# nrf54l10_flpr register map
Vendor: Nordic Semiconductor; Series: nrf54l; File version: 1
Registers are 32-bit, read-write, reset 0x0 unless marked. A register's access mark holds for its fields unless they carry their own. Offsets are from the block's base; [hi:lo] are bit positions; lines under a group give offsets from that group; {n}, {i} and the like mark numbered series; 'fields as' and 'values as' point back to an identical list.

## GLOBAL_GLITCHDET_S — Voltage glitch detectors
Base 0x5004B000
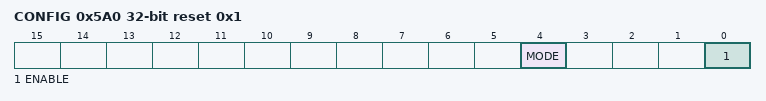
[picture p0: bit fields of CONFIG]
0x5A0 CONFIG reset 0x1 — Configuration for glitch detector
  [4] MODE — Glitch detector mode
    0=High pass filter mode; 1=Cap divider mode
  [0] ENABLE — Enable glitch detector
    0=Disable glitch detector; 1=Enable glitch detector

## GLOBAL_P2_NS — GPIO Port 0
Base 0x40050400
Same registers: GLOBAL_P1_NS 0x400D8200, GLOBAL_P0_NS 0x4010A000, GLOBAL_P2_S 0x50050400, GLOBAL_P1_S 0x500D8200, GLOBAL_P0_S 0x5010A000
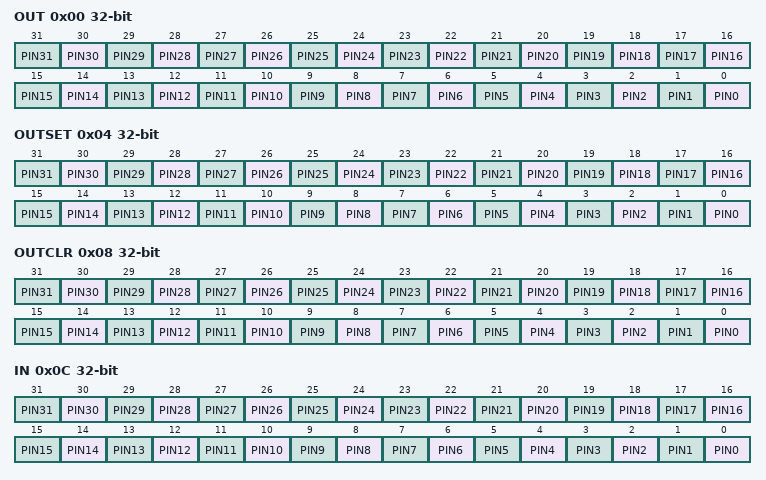
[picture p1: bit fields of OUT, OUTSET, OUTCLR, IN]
0x00 OUT — Write GPIO port
  [all] fields
    0=Low (Pin driver is low); 1=High (Pin driver is high)
  [n] PIN{n} (n=0..31)
0x04 OUTSET write-1-sets — Set individual bits in GPIO port
  [all] fields
    on read: 0=Low (Read: pin driver is low); 1=High (Read: pin driver is high) | on write: 1=Set (Write: writing a '1' sets the pin high; writing a '0' has no effect)
  [n] PIN{n} (n=0..31)
0x08 OUTCLR write-1-clears — Clear individual bits in GPIO port
  [all] fields
    on read: 0=Low (Read: pin driver is low); 1=High (Read: pin driver is high) | on write: 1=Clear (Write: writing a '1' sets the pin low; writing a '0' has no effect)
  [n] PIN{n} (n=0..31)
0x0C IN ro — Read GPIO port
  [all] fields
    0=Low (Pin input is low); 1=High (Pin input is high)
  [n] PIN{n} (n=0..31)
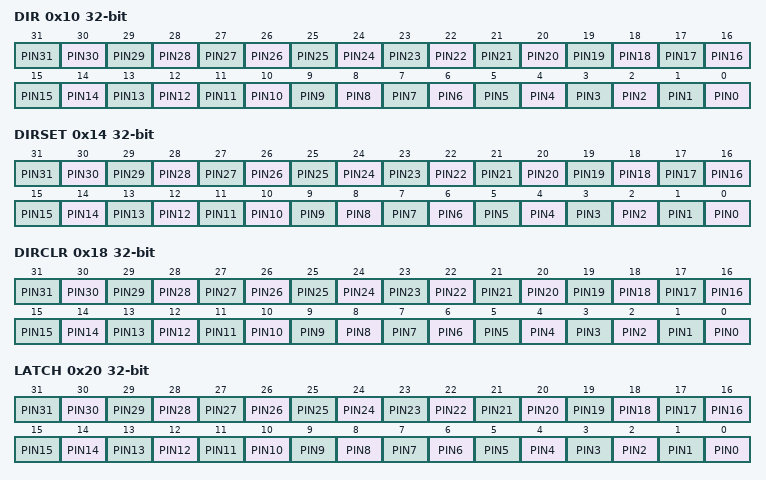
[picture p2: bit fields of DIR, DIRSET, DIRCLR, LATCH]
0x10 DIR — Direction of GPIO pins
  [all] fields
    0=Input (Pin set as input); 1=Output (Pin set as output)
  [n] PIN{n} (n=0..31)
0x14 DIRSET write-1-sets
  [all] fields
    on read: 0=Input (Read: pin set as input); 1=Output (Read: pin set as output) | on write: 1=Set (Write: writing a '1' sets pin to output; writing a '0' has no effect)
  [n] PIN{n} (n=0..31) — Set as output pin {n}
0x18 DIRCLR write-1-clears — DIR clear register
  [all] fields
    on read: 0=Input (Read: pin set as input); 1=Output (Read: pin set as output) | on write: 1=Clear (Write: writing a '1' sets pin to input; writing a '0' has no effect)
  [n] PIN{n} (n=0..31) — Set as input pin {n}
0x20 LATCH — Latch register indicating what GPIO pins that have met the criteria set in the PIN_CNF[n].SENSE registers
  [all] fields
    0=NotLatched (Criteria has not been met); 1=Latched (Criteria has been met)
  [n] PIN{n} (n=0..31) — Status on whether PIN{n} has met criteria set in PIN_CNF[{n}].SENSE register. Write '1' to clear.
0x24 DETECTMODE — Select between default DETECT signal behavior and LDETECT mode
  [0] DETECTMODE
    0=Default (DETECT directly connected to PIN DETECT signals); 1=LDETECT (Use the latched LDETECT behavior)
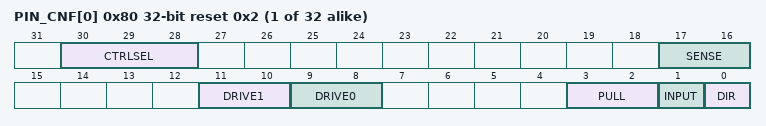
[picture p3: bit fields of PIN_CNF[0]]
{0x80+4i} PIN_CNF[{i}] (i=0..31) reset 0x2 — Description collection: Pin n configuration of GPIO pin
  [30:28] CTRLSEL — Select which module has direct control over this pin
    0=GPIO (GPIO or peripherals with PSEL registers); 1=VPR (VPR processor); 4=GRTC (GRTC peripheral)
  [17:16] SENSE — Pin sensing mechanism
    0=Disabled; 2=High (Sense for high level); 3=Low (Sense for low level)
  [11:10] DRIVE1 — Drive configuration for '1'
    0=S1 (Standard '1'); 1=H1 (High drive '1'); 2=D1 (Disconnect '1'(normally used for wired-or connections)); 3=E1 (Extra high drive '1')
  [9:8] DRIVE0 — Drive configuration for '0'
    0=S0 (Standard '0'); 1=H0 (High drive '0'); 2=D0 (Disconnect '0'(normally used for wired-or connections)); 3=E0 (Extra high drive '0')
  [3:2] PULL — Pull configuration
    0=Disabled (No pull); 1=Pull down on pin; 3=Pull up on pin
  [1] INPUT — Connect or disconnect input buffer
    0=Connect input buffer; 1=Disconnect input buffer
  [0] DIR — Pin direction. Same physical register as DIR register
    0=Input (Configure pin as an input pin); 1=Output (Configure pin as an output pin)

## GLOBAL_CTRLAP_NS — Control access port 0
Base 0x40052000
Same registers: GLOBAL_CTRLAP_S 0x50052000
0x100 EVENTS_RXREADY — RXSTATUS is changed to DataPending.
  [0] EVENTS_RXREADY
    0=NotGenerated (Event not generated); 1=Generated (Event generated)
0x104 EVENTS_TXDONE — TXSTATUS is changed to NoDataPending.
  [0] EVENTS_TXDONE
    values as EVENTS_RXREADY.EVENTS_RXREADY
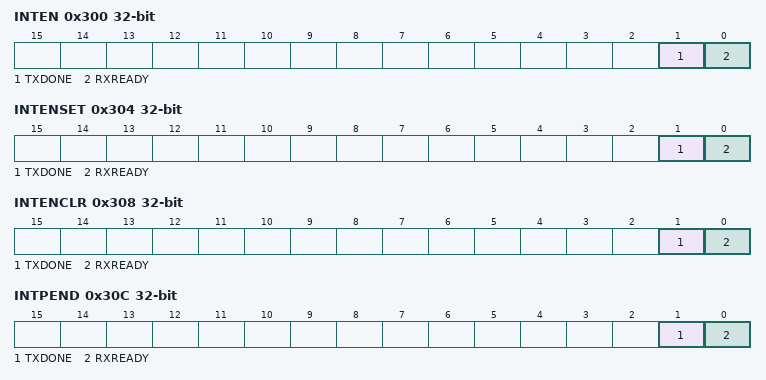
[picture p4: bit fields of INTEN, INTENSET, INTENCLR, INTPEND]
0x300 INTEN — Enable or disable interrupt
  [1] TXDONE — Enable or disable interrupt for event TXDONE
    0=Disabled; 1=Enabled
  [0] RXREADY — Enable or disable interrupt for event RXREADY
    0=Disabled; 1=Enabled
0x304 INTENSET — Enable interrupt
  [1] TXDONE — Write '1' to enable interrupt for event TXDONE
    on read: 0=Disabled (Read: Disabled); 1=Enabled (Read: Enabled) | on write: 1=Set (Enable)
  [0] RXREADY — Write '1' to enable interrupt for event RXREADY
    values as TXDONE
0x308 INTENCLR — Disable interrupt
  [1] TXDONE — Write '1' to disable interrupt for event TXDONE
    on read: 0=Disabled (Read: Disabled); 1=Enabled (Read: Enabled) | on write: 1=Clear (Disable)
  [0] RXREADY — Write '1' to disable interrupt for event RXREADY
    values as TXDONE
0x30C INTPEND ro — Pending interrupts
  [1] TXDONE — Read pending status of interrupt for event TXDONE
    on read: 0=NotPending (Read: Not pending); 1=Pending (Read: Pending)
  [0] RXREADY — Read pending status of interrupt for event RXREADY
    values as TXDONE
0x400 MAILBOX group — Unspecified
  0x00 RXDATA ro — Data sent from the debugger to the CPU.
    [31:0] RXDATA — Data received from debugger.
  0x04 RXSTATUS ro — Status to indicate if data sent from the debugger to the CPU has been read.
    [0] RXSTATUS — Status of data in register RXDATA.
      0=NoDataPending (No data is pending in register RXDATA.); 1=DataPending (Data is pending in register RXDATA.)
  0x80 TXDATA — Data sent from the CPU to the debugger.
    [31:0] TXDATA — Data sent to debugger.
  0x84 TXSTATUS ro — Status to indicate if data sent from the CPU to the debugger has been read.
    [0] TXSTATUS — Status of data in register TXDATA.
      0=NoDataPending (No data is pending in register TXDATA.); 1=DataPending (Data is pending in register TXDATA.)
0x500 ERASEPROTECT group — Unspecified
  0x00 LOCK rw-once — This register locks the ERASEPROTECT.DISABLE register from being written until next reset.
    [0] LOCK — Lock ERASEPROTECT.DISABLE register from being written until next reset.
      0=Unlocked (Register ERASEPROTECT.DISABLE is writeable.); 1=Locked (Register ERASEPROTECT.DISABLE is read-only.)
  0x04 DISABLE write-once — This register disables the ERASEPROTECT register and performs an ERASEALL operation.
    [31:0] KEY — The ERASEALL sequence is initiated if the value of the KEY fields are non-zero and the KEY fields match on both the CPU and debugger sides.
0x520 RESET wo — System reset request.
  [2:0] RESET — Reset request
    0=No reset is generated; 1=SoftReset (Perform a device soft reset); 2=HardReset (Perform a device hard reset); 4=PinReset (Perform a device pin reset)

## Notices in the file
Copyright (c) 2010 - 2025, Nordic Semiconductor ASA All rights reserved.
SPDX-License-Identifier: BSD-3-Clause
Redistribution and use in source and binary forms, with or without
modification, are permitted provided that the following conditions are met:
1. Redistributions of source code must retain the above copyright notice, this
list of conditions and the following disclaimer.
2. Redistributions in binary form must reproduce the above copyright
notice, this list of conditions and the following disclaimer in the
documentation and/or other materials provided with the distribution.
3. Neither the name of Nordic Semiconductor ASA nor the names of its
contributors may be used to endorse or promote products derived from this
software without specific prior written permission.
THIS SOFTWARE IS PROVIDED BY THE COPYRIGHT HOLDERS AND CONTRIBUTORS "AS IS"
AND ANY EXPRESS OR IMPLIED WARRANTIES, INCLUDING, BUT NOT LIMITED TO, THE
IMPLIED WARRANTIES OF MERCHANTABILITY, AND FITNESS FOR A PARTICULAR PURPOSE
ARE DISCLAIMED. IN NO EVENT SHALL NORDIC SEMICONDUCTOR ASA OR CONTRIBUTORS BE
LIABLE FOR ANY DIRECT, INDIRECT, INCIDENTAL, SPECIAL, EXEMPLARY, OR
CONSEQUENTIAL DAMAGES (INCLUDING, BUT NOT LIMITED TO, PROCUREMENT OF
SUBSTITUTE GOODS OR SERVICES; LOSS OF USE, DATA, OR PROFITS; OR BUSINESS
INTERRUPTION) HOWEVER CAUSED AND ON ANY THEORY OF LIABILITY, WHETHER IN
CONTRACT, STRICT LIABILITY, OR TORT (INCLUDING NEGLIGENCE OR OTHERWISE)
ARISING IN ANY WAY OUT OF THE USE OF THIS SOFTWARE, EVEN IF ADVISED OF THE
POSSIBILITY OF SUCH DAMAGE.
